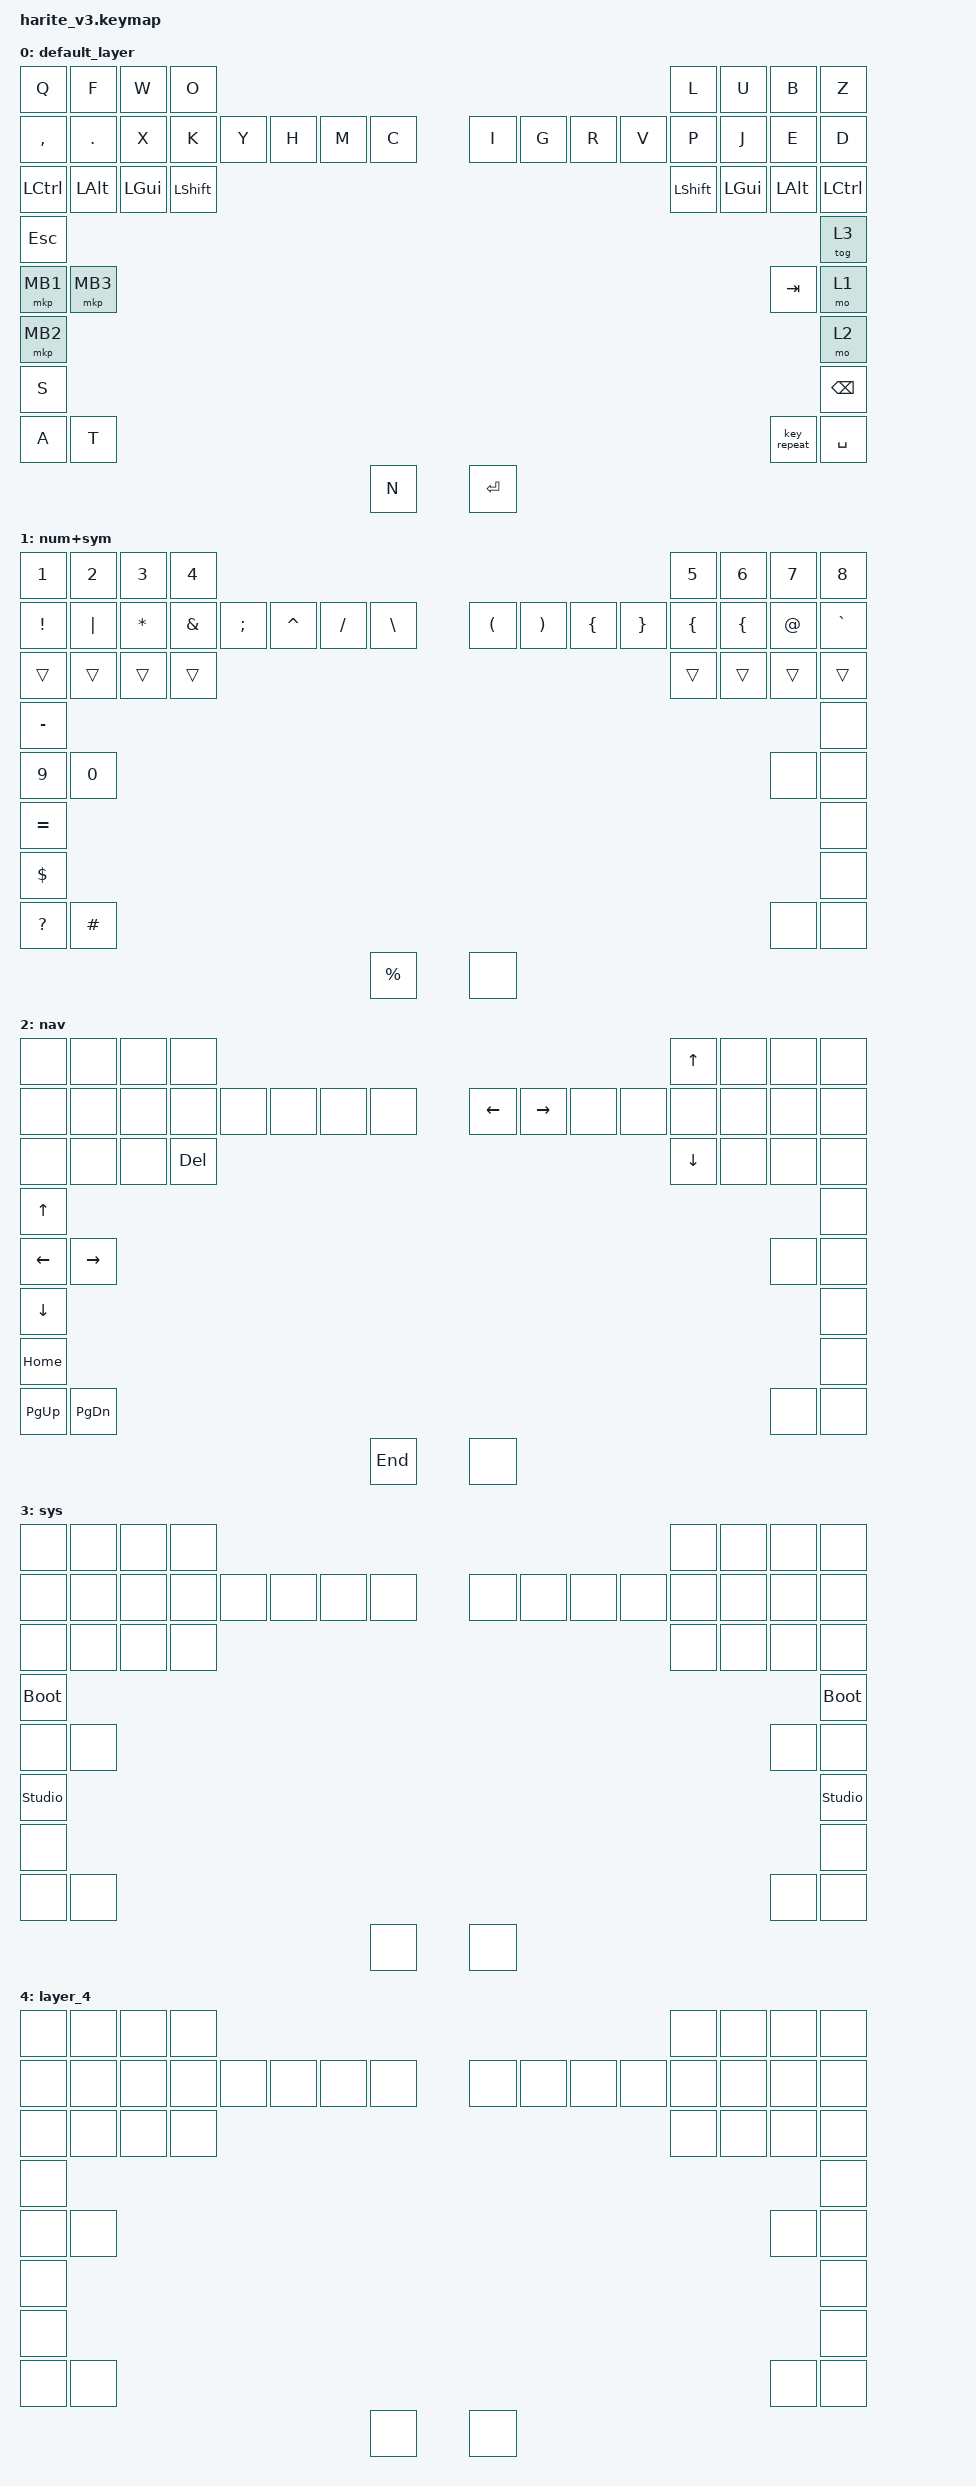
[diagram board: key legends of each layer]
#include <behaviors.dtsi>
#include <dt-bindings/zmk/keys.h>
#include <dt-bindings/zmk/bt.h>
#include <dt-bindings/zmk/pointing.h>
#include <input/processors.dtsi>
#include <dt-bindings/zmk/mouse.h>

/ {
    keymap {
        compatible = "zmk,keymap";

        default_layer {
            bindings = <
                      &kp Q              &kp F              &kp W              &kp O               &kp L              &kp U              &kp B              &kp Z
                &kp COMMA   &kp DOT &kp X     &kp K  &kp Y       &kp H  &kp M       &kp C   &kp I       &kp G  &kp R       &kp V  &kp P        &kp J  &kp E       &kp D
                      &kp LCTRL          &kp LALT           &kp LGUI           &kp LSHFT           &kp LSHFT          &kp LGUI           &kp LALT           &kp LCTRL

                                                                               &kp ESC             &tog 3
                                                                         &mkp MB1    &mkp MB3&kp TAB     &mo 1
                                                                               &mkp MB2            &mo 2
                                                                               &kp S               &kp BSPC
                                                                         &kp A       &kp T   &key_repeat &kp SPACE
                                                                               &kp N               &kp ENTER
            >;
        };
        num+sym {
            bindings = <
                      &kp N1             &kp N2             &kp N3             &kp N4              &kp N5             &kp N6             &kp N7             &kp N8
                &kp EXCL     &kp PIPE &kp STAR    &kp AMPS&kp SEMI   &kp CARET&kp FSLH  &kp BSLH&kp LPAR    &kp RPAR&kp LBRC &kp RBRC &kp LBRC    &kp LBRC&kp AT       &kp GRAVE
                      &trans             &trans             &trans             &trans              &trans             &trans             &trans             &trans

                                                                               &kp MINUS           &none
                                                                         &kp N9      &kp N0  &none       &none
                                                                               &kp EQUAL               &none
                                                                               &kp DOLLAR          &none
                                                                         &kp QMARK   &kp HASH   &none       &none
                                                                               &kp PERCENT         &none
            >;
        };
        nav {
            bindings = <
                      &none              &none              &none              &none               &kp UP              &none              &none              &none
                &none       &none  &none       &none  &none       &none  &none       &none   &kp LEFT    &kp RIGHT  &none       &none  &none       &none  &none       &none
                      &none              &none              &none              &kp DELETE          &kp DOWN              &none              &none              &none

                                                                               &kp UP              &none
                                                                         &kp LEFT    &kp RIGHT &none      &none
                                                                               &kp DOWN            &none
                                                                               &kp HOME            &none
                                                                         &kp PAGE_UP &kp PAGE_DOWN &none &none
                                                                               &kp END             &none
            >;
        };
        sys {
            bindings = <
                      &none              &none              &none              &none               &none              &none              &none              &none
                &none       &none  &none       &none  &none       &none  &none       &none   &none       &none  &none       &none  &none       &none  &none       &none
                      &none              &none              &none              &none               &none              &none              &none              &none

                                                                               &bootloader         &bootloader
                                                                         &none       &none   &none       &none
                                                                               &studio_unlock      &studio_unlock
                                                                               &none               &none
                                                                         &none       &none   &none       &none
                                                                               &none               &none
            >;
        };
        layer_4 {
            bindings = <
                      &none              &none              &none              &none               &none              &none              &none              &none
                &none       &none  &none       &none  &none       &none  &none       &none   &none       &none  &none       &none  &none       &none  &none       &none
                      &none              &none              &none              &none               &none              &none              &none              &none

                                                                               &none               &none
                                                                         &none       &none   &none       &none
                                                                               &none               &none
                                                                               &none               &none
                                                                         &none       &none   &none       &none
                                                                               &none               &none
            >;
        };
        /* Here are extra layers that can be enabled by pressing + in zmk studio */
        extra1 {
            status = "reserved";
        };
        extra2 {
            status = "reserved";
        };
    };

    /* PMW3310 */
    /* trackball_listener { */
    /*   compatible = "zmk,input-listener"; */
    /*   device = <&trackball>; */
    /* }; */
    /* Thumbstick */
    /* anin0: analog_input_0 { */
    /*   compatible = "zmk,analog-input"; */
    /*   status = "disabled"; */
    /*   sampling-hz = <100>; */
    /*   x-ch { */
    /*     io-channels = <&adc 2>; */
    /*     mv-mid = <1667>; */
    /*     mv-min-max = <3738>; */
    /*     mv-deadzone = <300>; */
    /*     scale-multiplier = <1>; */
    /*     scale-divisor = <1000>; */
    /*     invert; */
    /*     evt-type = <INPUT_EV_REL>; */
    /*     input-code = <INPUT_REL_X>; */
    /*   }; */
    /*   y-ch { */
    /*     io-channels = <&adc 3>; */
    /*     mv-mid = <2055>; */
    /*     mv-min-max = <3718>; */
    /*     mv-deadzone = <300>; */
    /*     scale-multiplier = <1>; */
    /*     scale-divisor = <1000>; */
    /*     evt-type = <INPUT_EV_REL>; */
    /*     input-code = <INPUT_REL_Y>; */
    /*   }; */
    /* }; */
    /* analog_input_listener { */
    /*     status = "okay"; */
    /*     compatible = "zmk,input-listener"; */
    /*     device = <&anin0>; */
    /*     input-processors = <&zip_xy_to_scroll_mapper>; */
    /* }; */
 };

/* Cirque */
&spi0 {
    status = "okay";
    glidepoint: glidepoint@0 {
        status = "okay";
    };
};

/* PMW3310 */
/* &spi1 { */
/*     status = "okay"; */
/*     trackball: trackball@0 { */
/*         status = "okay"; */
/*     }; */
/* }; */

/* Thumbstick */
/* &adc { */
/* 	status = "okay"; */
/* }; */

